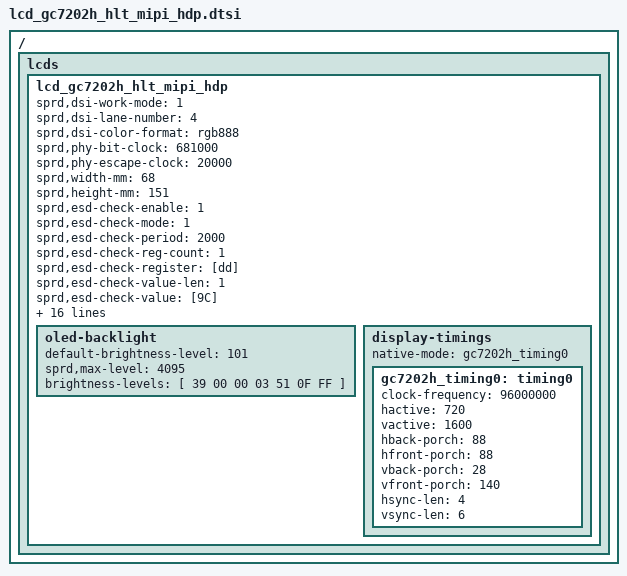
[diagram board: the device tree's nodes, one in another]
/ {
	fragment {
		target-path = "/";
		__overlay__ {
				lcds {
					lcd_gc7202h_hlt_mipi_hdp: lcd_gc7202h_hlt_mipi_hdp {

						sprd,dsi-work-mode = <1>; /* 1:video burst mode  2:pluse mode*/
						sprd,dsi-lane-number = <4>;
						sprd,dsi-color-format = "rgb888";

						sprd,phy-bit-clock = <681000>;	/* kbps */
						sprd,phy-escape-clock = <20000>;/* kHz */

						sprd,width-mm = <68>;
						sprd,height-mm = <151>;

						sprd,esd-check-enable = <1>;
						sprd,esd-check-mode = <1>;
						sprd,esd-check-period = <2000>;
						sprd,esd-check-reg-count = <1>;
						sprd,esd-check-register = [dd];
						sprd,esd-check-value-len = <1>;
						sprd,esd-check-value = [9C];

						sprd,reset-on-sequence = <1 10>, <0 10>, <1 25>;
						sprd,reset-off-sequence = <1 70>, <0 10>;

						sprd,use-dcs-write;
						sprd,bta-enable = <0>; //move to TP driver
						sprd,bta-check-register = <0xdd>;

						sprd,initial-command = [
						39 00 00 04 FF 55 AA 66
						29 00 00 02 FF B3
						29 00 00 02 2B 0C
						29 00 00 02 29 3F
						29 00 00 02 28 C0
						29 00 00 02 2A 03
						29 00 00 02 68 0F

						29 00 00 02 FF 10
						29 00 00 02 FB 00
						29 00 00 02 FF 20
						29 00 00 02 FB 00
						29 00 00 02 FF 21
						29 00 00 02 FB 00
						29 00 00 02 FF 22
						29 00 00 02 FB 00
						29 00 00 02 FF 23
						29 00 00 02 FB 00

						29 00 00 02 FF 27
						29 00 00 02 FB 00

						29 00 00 02 FF 26
						29 00 00 02 FB 00

						29 00 00 02 FF 28
						29 00 00 02 FB 00
						29 00 00 02 FF B3
						29 00 00 02 FB 00
						//更新AFE CODE 区域
						29 00 00 02 FF 28
						29 00 00 02 53 44
						29 00 00 02 50 4C
						29 00 00 02 52 53
						29 00 00 02 4D A2
						29 00 00 02 FF 20
						29 00 00 02 A5 00
						29 00 00 02 A6 FF
						29 00 00 02 A9 00
						29 00 00 02 AA FF
						29 00 00 02 D3 06

						29 00 00 02 2D 1F
						29 00 00 02 2E 42
						29 00 00 02 2F 14

						29 00 00 02 FF 22

						29 00 00 02 1F 06
						29 00 00 02 FF B3
						29 00 00 02 3E 03

						29 00 00 02 58 84
						29 00 00 02 53 1A
						29 00 00 02 82 19


						29 00 00 02 4A 0F
						29 00 00 02 7D 80
						29 00 00 02 5B 4B
						29 00 00 02 48 26
						29 00 00 02 7C 8C
						29 00 00 02 FF 10
						29 00 00 03 71 1F 98
						//TCON AND GOA TIMING
						29 00 00 02 FF 20
						29 00 00 02 A3 45
						29 00 00 02 A7 45
						29 00 00 02 FF 26
						29 00 00 02 1C 29
						29 00 00 02 FF B3
						29 00 00 02 B4 44
						29 00 00 02 3F 37
						29 00 00 02 5E 10
						29 00 00 02 FF 22
						29 00 00 02 E4 01
						29 00 00 02 01 06
						29 00 00 02 02 40
						29 00 00 02 25 08
						29 00 00 02 26 00
						29 00 00 02 2E 6F
						29 00 00 02 2F 00
						29 00 00 02 36 0D
						29 00 00 02 37 00
						29 00 00 02 3F 6F
						29 00 00 02 40 00
						29 00 00 02 FF 28
						29 00 00 02 01 25
						29 00 00 02 02 1A
						29 00 00 02 03 1A
						29 00 00 02 04 02
						29 00 00 02 05 20
						29 00 00 02 06 21
						29 00 00 02 07 08
						29 00 00 02 08 0A
						29 00 00 02 09 0C
						29 00 00 02 0A 0E
						29 00 00 02 0B 10
						29 00 00 02 0C 12
						29 00 00 02 0D 00
						29 00 00 02 0E 25
						29 00 00 02 0F 25
						29 00 00 02 10 25
						29 00 00 02 11 25
						29 00 00 02 12 25
						29 00 00 02 13 25
						29 00 00 02 14 25
						29 00 00 02 15 25
						29 00 00 02 16 25
						29 00 00 02 17 25
						29 00 00 02 18 1A
						29 00 00 02 19 1A
						29 00 00 02 1A 03
						29 00 00 02 1B 20
						29 00 00 02 1C 21
						29 00 00 02 1D 09
						29 00 00 02 1E 0B
						29 00 00 02 1F 0D
						29 00 00 02 20 0F
						29 00 00 02 21 11
						29 00 00 02 22 13
						29 00 00 02 23 01
						29 00 00 02 24 25
						29 00 00 02 25 25
						29 00 00 02 26 25
						29 00 00 02 27 25
						29 00 00 02 28 25
						29 00 00 02 29 25
						29 00 00 02 2A 25
						29 00 00 02 2B 25
						29 00 00 02 2D 25
						29 00 00 02 30 00
						29 00 00 02 31 00
						29 00 00 02 34 00
						29 00 00 02 35 15
						29 00 00 02 38 00
						29 00 00 02 39 00
						29 00 00 02 3A 01
						29 00 00 02 3B 05
						29 00 00 02 2F 1D
						29 00 00 02 FF 21
						29 00 00 02 7E 07
						29 00 00 02 7F 24
						29 00 00 02 8B 24
						29 00 00 02 97 24
						29 00 00 02 80 04
						29 00 00 02 8C 00
						29 00 00 02 98 1B
						29 00 00 02 AF 42
						29 00 00 02 B0 42
						29 00 00 02 B1 42
						29 00 00 02 83 05
						29 00 00 02 8F 05
						29 00 00 02 9B 05
						29 00 00 02 84 5F
						29 00 00 02 90 5F
						29 00 00 02 9C 5F
						29 00 00 02 85 5F
						29 00 00 02 91 5F
						29 00 00 02 9D 5F
						29 00 00 02 87 0D
						29 00 00 02 93 05
						29 00 00 02 9F 09
						29 00 00 02 82 70
						29 00 00 02 8E 70
						29 00 00 02 9A 70
						29 00 00 02 2B 00
						29 00 00 02 2E 00
						29 00 00 02 88 A7
						29 00 00 02 89 20
						29 00 00 02 8A 33
						29 00 00 02 94 A7
						29 00 00 02 95 20
						29 00 00 02 96 33
						29 00 00 02 A0 A7
						29 00 00 02 A1 20
						29 00 00 02 A2 33
						29 00 00 02 45 0F
						29 00 00 02 46 74
						29 00 00 02 4C 74
						29 00 00 02 52 74
						29 00 00 02 58 74
						29 00 00 02 47 05
						29 00 00 02 4D 04
						29 00 00 02 53 20
						29 00 00 02 59 21
						29 00 00 02 76 44
						29 00 00 02 77 44
						29 00 00 02 78 44
						29 00 00 02 79 44
						29 00 00 02 49 5F
						29 00 00 02 4A 5F
						29 00 00 02 4F 5F
						29 00 00 02 50 5F
						29 00 00 02 55 5F
						29 00 00 02 56 5F
						29 00 00 02 5B 5F
						29 00 00 02 5C 5F
						29 00 00 02 CA 03
						29 00 00 02 CB 3C
						29 00 00 02 CD 3C
						29 00 00 02 CC 20
						29 00 00 02 CE 20
						29 00 00 02 CF 76
						29 00 00 02 D0 72
						29 00 00 02 C2 84
						29 00 00 02 C6 46
						29 00 00 02 FF 22
						29 00 00 02 05 10
						29 00 00 02 08 10
						29 00 00 02 FF 20

						29 00 00 02 C3 00
						29 00 00 02 C4 71
						29 00 00 02 C5 00
						29 00 00 02 C6 71
						29 00 00 02 B3 00
						29 00 00 02 B4 20
						29 00 00 02 B5 00
						29 00 00 02 B6 DC
						29 00 00 02 FF 28
						29 00 00 02 3D 41
						29 00 00 02 3E 41
						29 00 00 02 3F 5A
						29 00 00 02 40 5A
						29 00 00 02 45 45
						29 00 00 02 46 45
						29 00 00 02 47 57
						29 00 00 02 48 57
						29 00 00 02 5A 8E
						29 00 00 02 5B 8E
						//29 00 00 02 62 9B   ////VCOM 寄存器 烧录VCOM须屏蔽
						//OSC TRIM 50.28MHz   TP 60.34M
						29 00 00 02 FF 20
						29 00 00 02 7E 01
						29 00 00 02 7F 00
						29 00 00 02 80 64
						29 00 00 02 81 00
						29 00 00 02 82 00
						29 00 00 02 83 64
						29 00 00 02 84 64
						29 00 00 02 85 2E
						29 00 00 02 86 21
						29 00 00 02 87 2E
						29 00 00 02 88 21
						29 00 00 02 8A 0A
						29 00 00 02 8B 0A
						//GAMMA
						29 00 00 02 FF 23
						29 00 00 02 29 03
						39 00 00 11 01 00 0A 00 1B 00 55 00 7A 00 99 00 B1 00 C5 00 DA
						39 00 00 11 02 00 E9 01 21 01 4A 01 87 01 B3 01 F8 02 33 02 35
						39 00 00 11 03 02 74 02 C0 02 EF 03 2A 03 50 03 7E 03 8B 03 98
						39 00 00 0D 04 03 A7 03 B7 03 CA 03 DD 03 F3 03 FF
						39 00 00 11 0D 00 0A 00 1B 00 55 00 7A 00 99 00 B1 00 C5 00 DA
						39 00 00 11 0E 00 E9 01 21 01 4A 01 87 01 B3 01 F8 02 33 02 35
						39 00 00 11 0F 02 74 02 C0 02 EF 03 2A 03 50 03 7E 03 8B 03 98
						39 00 00 0D 10 03 A7 03 B7 03 CA 03 DD 03 F3 03 FF
						//PWM&CABC
						29 00 00 02 2B 01    // PWM delay
						29 00 00 02 2D 65
						29 00 00 02 37 01
						29 00 00 02 2E 00
						29 00 00 02 32 00
						29 00 00 02 33 29    //PWM
						29 00 00 02 B9 31
						29 00 00 02 B8 B7
						29 00 00 02 35 CC
						29 00 00 02 36 0C
						29 00 00 02 30 00
						39 00 00 0D 1F D8 D8 D8 D8 D8 D8 D8 D8 D8 D8 D8 FF
						39 00 00 0D 20 00 00 00 00 00 00 00 00 00 00 00 00
						39 00 00 0D 21 D8 D8 D8 D8 D8 D8 D8 D8 D8 D8 D8 FF
						39 00 00 0D 22 00 00 00 00 00 00 00 00 00 00 00 00
						39 00 00 0D 23 D8 D8 D8 D8 D8 D8 D8 D8 D8 D8 D8 FF
						39 00 00 0D 24 00 00 00 00 00 00 00 00 00 00 00 00
						39 00 00 0D 25 10 24 38 4C 60 74 88 9C B0 C4 F0 FF

						29 00 00 02 FF 22
						29 00 00 02 EF 04   // DP  版本信息

						29 00 00 02 FF 10
						29 00 00 02 35 00
						29 00 00 02 53 2C
						39 00 00 03 51 00 00
						29 00 00 02 55 00

						29 00 00 02 FF 10
						29 00 00 02 36 08
						29 00 00 02 69 00
						05 78 00 01 11
						05 14 00 01 29

						];

						sprd,sleep-in-command = [
							39 00 00 04 FF 55 AA 66
							29 00 00 02 FF 20
							29 00 00 02 4A 01
							29 00 00 02 48 10
							29 00 00 02 49 00

							29 00 00 02 FF 10
							29 32 00 02 28 00
							29 78 00 02 10 00


							29 00 00 02 FB 00

							29 00 00 02 4F 01
						];//gesture off

						sprd,sleep-gesture-command = [
							39 00 00 04 FF 55 AA 66
							29 00 00 02 FF 20
							29 00 00 02 4A 01
							29 00 00 02 48 10
							29 00 00 02 49 00

							29 00 00 02 FF 10
							29 32 00 02 28 00

							29 78 00 02 10 00
						];//gesture on

						sprd,sleep-out-command = [
							05 78 00 01 11
							05 23 00 01 29
						];

						sprd,cabc-ui-mode = [
							15 00 00 02 55 01
						];

						sprd,cabc-mov-mode = [
							15 00 00 02 55 03
						];

						sprd,cabc-off-mode = [
							15 00 00 02 55 00
						];

						oled-backlight {
							default-brightness-level = <101>;
							sprd,max-level = <4095>;
							brightness-levels = [
								39 00 00 03 51 0F FF
							];
						};
						display-timings {
							native-mode = <&gc7202h_timing0>;
							gc7202h_timing0: timing0 {
								clock-frequency = <96000000>;
								hactive = <720>;
								vactive = <1600>;
								hback-porch = <88>;
								hfront-porch = <88>;
								vback-porch = <28>;
								vfront-porch = <140>;
								hsync-len = <4>;
								vsync-len = <6>;
							};
						};
					};
				};
		};
	};
};
